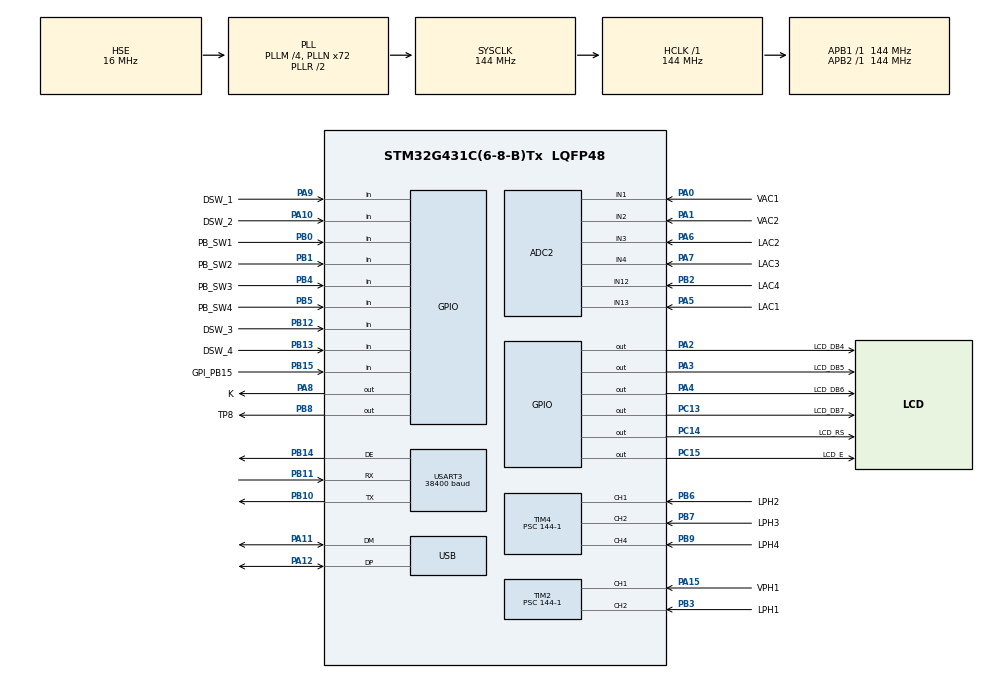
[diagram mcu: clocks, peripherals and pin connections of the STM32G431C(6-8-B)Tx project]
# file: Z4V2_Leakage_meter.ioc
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ADC1.Channel-0\#ChannelRegularConversion=ADC_CHANNEL_TEMPSENSOR_ADC1
ADC1.Channel-1\#ChannelRegularConversion=ADC_CHANNEL_VBAT
ADC1.Channel-2\#ChannelRegularConversion=ADC_CHANNEL_VREFINT
ADC1.DMAContinuousRequests=ENABLE
ADC1.ExternalTrigConv=ADC_EXTERNALTRIG_T7_TRGO
ADC1.NbrOfConversion=3
ADC1.NbrOfConversionFlag=1
ADC1.OffsetNumber-0\#ChannelRegularConversion=ADC_OFFSET_NONE
ADC1.OffsetNumber-1\#ChannelRegularConversion=ADC_OFFSET_NONE
ADC1.OffsetNumber-2\#ChannelRegularConversion=ADC_OFFSET_NONE
ADC1.Rank-0\#ChannelRegularConversion=1
ADC1.Rank-1\#ChannelRegularConversion=2
ADC1.Rank-2\#ChannelRegularConversion=3
ADC1.SamplingTime-0\#ChannelRegularConversion=ADC_SAMPLETIME_640CYCLES_5
ADC1.SamplingTime-1\#ChannelRegularConversion=ADC_SAMPLETIME_640CYCLES_5
ADC1.SamplingTime-2\#ChannelRegularConversion=ADC_SAMPLETIME_640CYCLES_5
ADC1.master=1
ADC2.Channel-0\#ChannelRegularConversion=ADC_CHANNEL_1
ADC2.Channel-1\#ChannelRegularConversion=ADC_CHANNEL_2
ADC2.Channel-2\#ChannelRegularConversion=ADC_CHANNEL_13
ADC2.Channel-3\#ChannelRegularConversion=ADC_CHANNEL_3
ADC2.Channel-4\#ChannelRegularConversion=ADC_CHANNEL_4
ADC2.Channel-5\#ChannelRegularConversion=ADC_CHANNEL_12
ADC2.DMAContinuousRequests=ENABLE
ADC2.ExternalTrigConv=ADC_EXTERNALTRIG_T8_TRGO
ADC2.NbrOfConversion=6
ADC2.NbrOfConversionFlag=1
ADC2.OffsetNumber-0\#ChannelRegularConversion=ADC_OFFSET_NONE
ADC2.OffsetNumber-1\#ChannelRegularConversion=ADC_OFFSET_NONE
ADC2.OffsetNumber-2\#ChannelRegularConversion=ADC_OFFSET_NONE
ADC2.OffsetNumber-3\#ChannelRegularConversion=ADC_OFFSET_NONE
ADC2.OffsetNumber-4\#ChannelRegularConversion=ADC_OFFSET_NONE
ADC2.OffsetNumber-5\#ChannelRegularConversion=ADC_OFFSET_NONE
ADC2.Rank-0\#ChannelRegularConversion=1
ADC2.Rank-1\#ChannelRegularConversion=2
ADC2.Rank-2\#ChannelRegularConversion=3
ADC2.Rank-3\#ChannelRegularConversion=4
ADC2.Rank-4\#ChannelRegularConversion=5
ADC2.Rank-5\#ChannelRegularConversion=6
ADC2.SamplingTime-0\#ChannelRegularConversion=ADC_SAMPLETIME_47CYCLES_5
ADC2.SamplingTime-1\#ChannelRegularConversion=ADC_SAMPLETIME_47CYCLES_5
ADC2.SamplingTime-2\#ChannelRegularConversion=ADC_SAMPLETIME_47CYCLES_5
ADC2.SamplingTime-3\#ChannelRegularConversion=ADC_SAMPLETIME_47CYCLES_5
ADC2.SamplingTime-4\#ChannelRegularConversion=ADC_SAMPLETIME_47CYCLES_5
ADC2.SamplingTime-5\#ChannelRegularConversion=ADC_SAMPLETIME_47CYCLES_5
Dma.ADC1.1.Direction=DMA_PERIPH_TO_MEMORY
Dma.ADC1.1.EventEnable=DISABLE
Dma.ADC1.1.Instance=DMA1_Channel2
Dma.ADC1.1.MemDataAlignment=DMA_MDATAALIGN_HALFWORD
Dma.ADC1.1.MemInc=DMA_MINC_ENABLE
Dma.ADC1.1.Mode=DMA_CIRCULAR
Dma.ADC1.1.PeriphDataAlignment=DMA_PDATAALIGN_HALFWORD
Dma.ADC1.1.PeriphInc=DMA_PINC_DISABLE
Dma.ADC1.1.Polarity=HAL_DMAMUX_REQ_GEN_RISING
Dma.ADC1.1.Priority=DMA_PRIORITY_LOW
Dma.ADC1.1.RequestNumber=1
Dma.ADC1.1.SignalID=NONE
Dma.ADC1.1.SyncEnable=DISABLE
Dma.ADC1.1.SyncPolarity=HAL_DMAMUX_SYNC_NO_EVENT
Dma.ADC1.1.SyncRequestNumber=1
Dma.ADC1.1.SyncSignalID=NONE
Dma.ADC2.0.Direction=DMA_PERIPH_TO_MEMORY
Dma.ADC2.0.EventEnable=DISABLE
Dma.ADC2.0.Instance=DMA1_Channel1
Dma.ADC2.0.MemDataAlignment=DMA_MDATAALIGN_HALFWORD
Dma.ADC2.0.MemInc=DMA_MINC_ENABLE
Dma.ADC2.0.Mode=DMA_CIRCULAR
Dma.ADC2.0.PeriphDataAlignment=DMA_PDATAALIGN_HALFWORD
Dma.ADC2.0.PeriphInc=DMA_PINC_DISABLE
Dma.ADC2.0.Polarity=HAL_DMAMUX_REQ_GEN_RISING
Dma.ADC2.0.Priority=DMA_PRIORITY_LOW
Dma.ADC2.0.RequestNumber=1
Dma.ADC2.0.SignalID=NONE
Dma.ADC2.0.SyncEnable=DISABLE
Dma.ADC2.0.SyncPolarity=HAL_DMAMUX_SYNC_NO_EVENT
Dma.ADC2.0.SyncRequestNumber=1
Dma.ADC2.0.SyncSignalID=NONE
Dma.Request0=ADC2
Dma.Request1=ADC1
FREERTOS.BinarySemaphores01=binSem_Flash,Static,binSem_ControlBlock,Available
FREERTOS.Queues01=queue_ADC,8,uint8_t,0,Static,queue_ADCBuffer,queue_ADCControlBlock;queue_USB,128,uint16_t,0,Static,queue_USBBuffer,queue_USBControlBlock
FREERTOS.Tasks01=tsk_USB,24,256,Start_tskUSB,Default,NULL,Static,tsk_USBBuffer,tsk_USBControlBlock;tsk_Calc,16,256,Start_tskCalc,Default,NULL,Static,tsk_CalcBuffer,tsk_CalcControlBlock;tsk_Ul,8,256,Start_taskUI,Default,NULL,Static,tsk_UlBuffer,tsk_UlControlBlock;tsk_MODBUS,40,128,Start_taskModbus,Default,NULL,Static,tsk_MODBUSBuffer,tsk_MODBUSControlBlock
FREERTOS.configENABLE_FPU=1
Mcu.Family=STM32G4
Mcu.Name=STM32G431C(6-8-B)Tx
Mcu.Package=LQFP48
NVIC.ADC1_2_IRQn=true\:5\:0\:false\:false\:true\:true\:true\:true\:true
NVIC.DMA1_Channel1_IRQn=true\:5\:0\:false\:false\:true\:true\:false\:true\:true
NVIC.DMA1_Channel2_IRQn=true\:5\:0\:false\:false\:true\:true\:false\:true\:true
NVIC.PriorityGroup=NVIC_PRIORITYGROUP_4
NVIC.TIM1_TRG_COM_TIM17_IRQn=true\:5\:0\:false\:false\:true\:false\:false\:true\:true
NVIC.TIM1_UP_TIM16_IRQn=true\:5\:0\:false\:false\:true\:true\:true\:true\:true
NVIC.TIM2_IRQn=true\:5\:0\:false\:false\:true\:true\:true\:true\:true
NVIC.TIM4_IRQn=true\:5\:0\:false\:false\:true\:true\:true\:true\:true
NVIC.TimeBase=TIM1_TRG_COM_TIM17_IRQn
NVIC.TimeBaseIP=TIM17
NVIC.USART3_IRQn=true\:5\:0\:false\:false\:true\:true\:true\:true\:true
NVIC.USB_LP_IRQn=true\:5\:0\:false\:false\:true\:true\:false\:true\:true
PA0.GPIO_Label=VAC1
PA0.Mode=IN1-Single-Ended
PA0.Signal=ADC2_IN1
PA1.GPIO_Label=VAC2
PA1.Mode=IN2-Single-Ended
PA1.Signal=ADC2_IN2
PA10.GPIO_Label=DSW_2
PA10.Signal=GPIO_Input
PA11.Mode=Device
PA11.Signal=USB_DM
PA12.Mode=Device
PA12.Signal=USB_DP
PA13.Mode=Serial_Wire
PA13.Signal=SYS_JTMS-SWDIO
PA14.Mode=Serial_Wire
PA14.Signal=SYS_JTCK-SWCLK
PA15.GPIO_Label=VPH1
PA15.Signal=S_TIM2_CH1
PA2.GPIO_Label=LCD_DB4
PA2.Signal=GPIO_Output
PA3.GPIO_Label=LCD_DB5
PA3.Signal=GPIO_Output
PA4.GPIO_Label=LCD_DB6
PA4.Signal=GPIO_Output
PA5.GPIO_Label=LAC1
PA5.Mode=IN13-Single-Ended
PA5.Signal=ADC2_IN13
PA6.GPIO_Label=LAC2
PA6.Mode=IN3-Single-Ended
PA6.Signal=ADC2_IN3
PA7.GPIO_Label=LAC3
PA7.Mode=IN4-Single-Ended
PA7.Signal=ADC2_IN4
PA8.GPIO_Label=K
PA8.Signal=GPIO_Output
PA9.GPIO_Label=DSW_1
PA9.Signal=GPIO_Input
PB0.GPIO_Label=PB_SW1
PB0.Signal=GPIO_Input
PB1.GPIO_Label=PB_SW2
PB1.Signal=GPIO_Input
PB10.Mode=Asynchronous
PB10.Signal=USART3_TX
PB11.Mode=Asynchronous
PB11.Signal=USART3_RX
PB12.GPIO_Label=DSW_3
PB12.Signal=GPIO_Input
PB13.GPIO_Label=DSW_4
PB13.Signal=GPIO_Input
PB14.Mode=Hardware Flow Control (RS485)
PB14.Signal=USART3_DE
PB15.GPIO_Label=GPI_PB15
PB15.Signal=GPIO_Input
PB2.GPIO_Label=LAC4
PB2.Mode=IN12-Single-Ended
PB2.Signal=ADC2_IN12
PB3.GPIO_Label=LPH1
PB3.Signal=S_TIM2_CH2
PB4.GPIO_Label=PB_SW3
PB4.Signal=GPIO_Input
PB5.GPIO_Label=PB_SW4
PB5.Signal=GPIO_Input
PB6.GPIO_Label=LPH2
PB6.Signal=S_TIM4_CH1
PB7.GPIO_Label=LPH3
PB7.Signal=S_TIM4_CH2
PB8-BOOT0.GPIO_Label=TP8
PB8-BOOT0.Signal=GPIO_Output
PB9.GPIO_Label=LPH4
PB9.Signal=S_TIM4_CH4
PC13.GPIO_Label=LCD_DB7
PC13.Signal=GPIO_Output
PC14-OSC32_IN.GPIO_Label=LCD_RS
PC14-OSC32_IN.Signal=GPIO_Output
PC15-OSC32_OUT.GPIO_Label=LCD_E
PC15-OSC32_OUT.Signal=GPIO_Output
PF0-OSC_IN.Mode=HSE-External-Oscillator
PF0-OSC_IN.Signal=RCC_OSC_IN
PF1-OSC_OUT.Mode=HSE-External-Oscillator
PF1-OSC_OUT.Signal=RCC_OSC_OUT
ProjectManager.HeapSize=0x200
ProjectManager.StackSize=0x400
ProjectManager.TargetToolchain=STM32CubeIDE
RCC.ADC12Freq_Value=144000000
RCC.AHBFreq_Value=144000000
RCC.APB1Freq_Value=144000000
RCC.APB1TimFreq_Value=144000000
RCC.APB2Freq_Value=144000000
RCC.APB2TimFreq_Value=144000000
RCC.CK48CLockSelection=RCC_USBCLKSOURCE_HSI48
RCC.CortexFreq_Value=144000000
RCC.EXTERNAL_CLOCK_VALUE=12288000
RCC.HCLKFreq_Value=144000000
RCC.HSE_VALUE=16000000
RCC.HSI48_VALUE=48000000
RCC.HSI_VALUE=16000000
RCC.LSE_VALUE=32768
RCC.PLLM=RCC_PLLM_DIV4
RCC.PLLN=72
RCC.PLLQ=RCC_PLLQ_DIV4
RCC.PLLSourceVirtual=RCC_PLLSOURCE_HSE
RCC.SYSCLKFreq_VALUE=144000000
RCC.SYSCLKSource=RCC_SYSCLKSOURCE_PLLCLK
RCC.USBFreq_Value=48000000
RCC.VCOOutputFreq_Value=288000000
SH.S_TIM2_CH1.0=TIM2_CH1,Input_Capture1_from_TI1
SH.S_TIM2_CH2.0=TIM2_CH2,Input_Capture2_from_TI2
SH.S_TIM4_CH1.0=TIM4_CH1,Input_Capture1_from_TI1
SH.S_TIM4_CH2.0=TIM4_CH2,Input_Capture2_from_TI2
SH.S_TIM4_CH4.0=TIM4_CH4,Input_Capture4_from_TI4
TIM1.PeriodNoDither=144-1
TIM1.Prescaler=1000-1
TIM15.Prescaler=1440-1
TIM2.Channel-Input_Capture1_from_TI1=TIM_CHANNEL_1
TIM2.Channel-Input_Capture2_from_TI2=TIM_CHANNEL_2
TIM2.ICPolarity_CH1=TIM_INPUTCHANNELPOLARITY_RISING
TIM2.ICPolarity_CH2=TIM_INPUTCHANNELPOLARITY_RISING
TIM2.PeriodNoDither=65535
TIM2.Prescaler=144-1
TIM2.TIM_MasterOutputTrigger=TIM_TRGO_RESET
TIM2.TIM_MasterSlaveMode=TIM_MASTERSLAVEMODE_DISABLE
TIM3.PeriodNoDither=65535
TIM3.Prescaler=144-1
TIM3.TIM_MasterOutputTrigger=TIM_TRGO_UPDATE
TIM3.TIM_MasterSlaveMode=TIM_MASTERSLAVEMODE_ENABLE
TIM4.Channel-Input_Capture1_from_TI1=TIM_CHANNEL_1
TIM4.Channel-Input_Capture2_from_TI2=TIM_CHANNEL_2
TIM4.Channel-Input_Capture4_from_TI4=TIM_CHANNEL_4
TIM4.ICPolarity_CH1=TIM_INPUTCHANNELPOLARITY_RISING
TIM4.ICPolarity_CH2=TIM_INPUTCHANNELPOLARITY_RISING
TIM4.ICPolarity_CH4=TIM_INPUTCHANNELPOLARITY_RISING
TIM4.Prescaler=144-1
TIM4.TIM_MasterOutputTrigger=TIM_TRGO_RESET
TIM4.TIM_MasterSlaveMode=TIM_MASTERSLAVEMODE_DISABLE
TIM7.PeriodNoDither=10000-1
TIM7.Prescaler=14400-1
TIM7.TIM_MasterOutputTrigger=TIM_TRGO_UPDATE
TIM8.PeriodNoDither=40000-1
TIM8.TIM_MasterOutputTrigger=TIM_TRGO_UPDATE
USART3.BaudRate=38400
USART3.FIFOMode=FIFOMODE_ENABLE
USART3.StopBits=STOPBITS_2
USART3.VirtualMode-Asynchronous=VM_ASYNC
USART3.VirtualMode-Hardware\ Flow\ Control\ (RS485)=VM_ASYNC
USB_DEVICE.CLASS_NAME_FS=CDC
USB_DEVICE.VirtualMode=Cdc
USB_DEVICE.VirtualModeFS=Cdc_FS
VP_ADC1_TempSens_Input.Mode=IN-TempSens
VP_ADC1_Vbat_Input.Mode=IN-Vbat
VP_ADC1_Vref_Input.Mode=IN-Vrefint
VP_CRC_VS_CRC.Mode=CRC_Activate
VP_FREERTOS_VS_CMSIS_V2.Mode=CMSIS_V2
VP_SYS_VS_DBSignals.Mode=DisableDeadBatterySignals
VP_SYS_VS_tim17.Mode=TIM17
VP_TIM15_VS_ClockSourceINT.Mode=Internal
VP_TIM1_VS_ClockSourceINT.Mode=Internal
VP_TIM2_VS_ClockSourceINT.Mode=Internal
VP_TIM2_VS_ClockSourceITR.Mode=TriggerSource_ITR2
VP_TIM2_VS_ControllerModeTrigger.Mode=Trigger Mode
VP_TIM3_VS_ClockSourceINT.Mode=Internal
VP_TIM4_VS_ClockSourceINT.Mode=Internal
VP_TIM4_VS_ClockSourceITR.Mode=TriggerSource_ITR2
VP_TIM4_VS_ControllerModeTrigger.Mode=Trigger Mode
VP_TIM7_VS_ClockSourceINT.Mode=Enable_Timer
VP_TIM8_VS_ClockSourceINT.Mode=Internal
VP_USB_DEVICE_VS_USB_DEVICE_CDC_FS.Mode=CDC_FS
board=custom

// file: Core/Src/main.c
/* USER CODE BEGIN Header */
/**
  ******************************************************************************
  * @file           : main.c
  * @brief          : Main program body
  ******************************************************************************
  * @attention
  *
  * Copyright (c) 2026 STMicroelectronics.
  * All rights reserved.
  *
  * This software is licensed under terms that can be found in the LICENSE file
  * in the root directory of this software component.
  * If no LICENSE file comes with this software, it is provided AS-IS.
  *
  ******************************************************************************
  */
/* USER CODE END Header */
#include "main.h"
#include "cmsis_os.h"
#include "usb_device.h"

/* USER CODE BEGIN Includes */
#include "prj.h"
/* USER CODE END Includes */

typedef StaticTask_t osStaticThreadDef_t;
typedef StaticQueue_t osStaticMessageQDef_t;
typedef StaticSemaphore_t osStaticSemaphoreDef_t;

ADC_HandleTypeDef hadc1;
ADC_HandleTypeDef hadc2;
DMA_HandleTypeDef hdma_adc1;
DMA_HandleTypeDef hdma_adc2;

CRC_HandleTypeDef hcrc;

TIM_HandleTypeDef htim1;
TIM_HandleTypeDef htim2;
TIM_HandleTypeDef htim3;
TIM_HandleTypeDef htim4;
TIM_HandleTypeDef htim7;
TIM_HandleTypeDef htim8;
TIM_HandleTypeDef htim15;

UART_HandleTypeDef huart3;

/* Definitions for tsk_USB */
osThreadId_t tsk_USBHandle;
uint32_t tsk_USBBuffer[ 256 ];
osStaticThreadDef_t tsk_USBControlBlock;
const osThreadAttr_t tsk_USB_attributes = {
  .name = "tsk_USB",
  .stack_mem = &tsk_USBBuffer[0],
  .stack_size = sizeof(tsk_USBBuffer),
  .cb_mem = &tsk_USBControlBlock,
  .cb_size = sizeof(tsk_USBControlBlock),
  .priority = (osPriority_t) osPriorityNormal,
};
/* Definitions for tsk_Calc */
osThreadId_t tsk_CalcHandle;
uint32_t tsk_CalcBuffer[ 256 ];
osStaticThreadDef_t tsk_CalcControlBlock;
const osThreadAttr_t tsk_Calc_attributes = {
  .name = "tsk_Calc",
  .stack_mem = &tsk_CalcBuffer[0],
  .stack_size = sizeof(tsk_CalcBuffer),
  .cb_mem = &tsk_CalcControlBlock,
  .cb_size = sizeof(tsk_CalcControlBlock),
  .priority = (osPriority_t) osPriorityBelowNormal,
};
/* Definitions for tsk_Ul */
osThreadId_t tsk_UlHandle;
uint32_t tsk_UlBuffer[ 256 ];
osStaticThreadDef_t tsk_UlControlBlock;
const osThreadAttr_t tsk_Ul_attributes = {
  .name = "tsk_Ul",
  .stack_mem = &tsk_UlBuffer[0],
  .stack_size = sizeof(tsk_UlBuffer),
  .cb_mem = &tsk_UlControlBlock,
  .cb_size = sizeof(tsk_UlControlBlock),
  .priority = (osPriority_t) osPriorityLow,
};
/* Definitions for tsk_MODBUS */
osThreadId_t tsk_MODBUSHandle;
uint32_t tsk_MODBUSBuffer[ 128 ];
osStaticThreadDef_t tsk_MODBUSControlBlock;
const osThreadAttr_t tsk_MODBUS_attributes = {
  .name = "tsk_MODBUS",
  .stack_mem = &tsk_MODBUSBuffer[0],
  .stack_size = sizeof(tsk_MODBUSBuffer),
  .cb_mem = &tsk_MODBUSControlBlock,
  .cb_size = sizeof(tsk_MODBUSControlBlock),
  .priority = (osPriority_t) osPriorityHigh,
};
/* Definitions for queue_ADC */
osMessageQueueId_t queue_ADCHandle;
uint8_t queue_ADCBuffer[ 8 * sizeof( uint8_t ) ];
osStaticMessageQDef_t queue_ADCControlBlock;
const osMessageQueueAttr_t queue_ADC_attributes = {
  .name = "queue_ADC",
  .cb_mem = &queue_ADCControlBlock,
  .cb_size = sizeof(queue_ADCControlBlock),
  .mq_mem = &queue_ADCBuffer,
  .mq_size = sizeof(queue_ADCBuffer)
};
/* Definitions for queue_USB */
osMessageQueueId_t queue_USBHandle;
uint8_t queue_USBBuffer[ 128 * sizeof( uint16_t ) ];
osStaticMessageQDef_t queue_USBControlBlock;
const osMessageQueueAttr_t queue_USB_attributes = {
  .name = "queue_USB",
  .cb_mem = &queue_USBControlBlock,
  .cb_size = sizeof(queue_USBControlBlock),
  .mq_mem = &queue_USBBuffer,
  .mq_size = sizeof(queue_USBBuffer)
};
/* Definitions for binSem_Flash */
osSemaphoreId_t binSem_FlashHandle;
osStaticSemaphoreDef_t binSem_ControlBlock;
const osSemaphoreAttr_t binSem_Flash_attributes = {
  .name = "binSem_Flash",
  .cb_mem = &binSem_ControlBlock,
  .cb_size = sizeof(binSem_ControlBlock),
};

void SystemClock_Config(void);
static void MX_GPIO_Init(void);
static void MX_DMA_Init(void);
static void MX_ADC2_Init(void);
static void MX_TIM3_Init(void);
static void MX_TIM4_Init(void);
static void MX_USART3_UART_Init(void);
static void MX_TIM2_Init(void);
static void MX_ADC1_Init(void);
static void MX_TIM7_Init(void);
static void MX_TIM8_Init(void);
static void MX_CRC_Init(void);
static void MX_TIM15_Init(void);
static void MX_TIM1_Init(void);
void Start_tskUSB(void *argument);
void Start_tskCalc(void *argument);
void Start_taskUI(void *argument);
void Start_taskModbus(void *argument);

int main(void)
{

  /* MCU Configuration--------------------------------------------------------*/

  /* Reset of all peripherals, Initializes the Flash interface and the Systick. */
  HAL_Init();

  /* Configure the system clock */
  SystemClock_Config();

  /* Initialize all configured peripherals */
  MX_GPIO_Init();
  MX_DMA_Init();
  MX_ADC2_Init();
  MX_TIM3_Init();
  MX_TIM4_Init();
  MX_USART3_UART_Init();
  MX_TIM2_Init();
  MX_ADC1_Init();
  MX_TIM7_Init();
  MX_TIM8_Init();
  MX_CRC_Init();
  MX_TIM15_Init();
  MX_TIM1_Init();

  /* Init scheduler */
  osKernelInitialize();

  /* Create the semaphores(s) */
  /* creation of binSem_Flash */
  binSem_FlashHandle = osSemaphoreNew(1, 1, &binSem_Flash_attributes);

  /* Create the queue(s) */
  /* creation of queue_ADC */
  queue_ADCHandle = osMessageQueueNew (8, sizeof(uint8_t), &queue_ADC_attributes);

  /* creation of queue_USB */
  queue_USBHandle = osMessageQueueNew (128, sizeof(uint16_t), &queue_USB_attributes);

  /* Create the thread(s) */
  /* creation of tsk_USB */
  tsk_USBHandle = osThreadNew(Start_tskUSB, NULL, &tsk_USB_attributes);

  /* creation of tsk_Calc */
  tsk_CalcHandle = osThreadNew(Start_tskCalc, NULL, &tsk_Calc_attributes);

  /* creation of tsk_Ul */
  tsk_UlHandle = osThreadNew(Start_taskUI, NULL, &tsk_Ul_attributes);

  /* creation of tsk_MODBUS */
  tsk_MODBUSHandle = osThreadNew(Start_taskModbus, NULL, &tsk_MODBUS_attributes);

  /* Start scheduler */
  osKernelStart();

  /* We should never get here as control is now taken by the scheduler */

  /* Infinite loop */
  while (1)
  {

  }
}

void SystemClock_Config(void)
{
  RCC_OscInitTypeDef RCC_OscInitStruct = {0};
  RCC_ClkInitTypeDef RCC_ClkInitStruct = {0};

  /** Configure the main internal regulator output voltage
  */
  HAL_PWREx_ControlVoltageScaling(PWR_REGULATOR_VOLTAGE_SCALE1);

  /** Initializes the RCC Oscillators according to the specified parameters
  * in the RCC_OscInitTypeDef structure.
  */
  RCC_OscInitStruct.OscillatorType = RCC_OSCILLATORTYPE_HSI48|RCC_OSCILLATORTYPE_HSE;
  RCC_OscInitStruct.HSEState = RCC_HSE_ON;
  RCC_OscInitStruct.HSI48State = RCC_HSI48_ON;
  RCC_OscInitStruct.PLL.PLLState = RCC_PLL_ON;
  RCC_OscInitStruct.PLL.PLLSource = RCC_PLLSOURCE_HSE;
  RCC_OscInitStruct.PLL.PLLM = RCC_PLLM_DIV4;
  RCC_OscInitStruct.PLL.PLLN = 72;
  RCC_OscInitStruct.PLL.PLLP = RCC_PLLP_DIV2;
  RCC_OscInitStruct.PLL.PLLQ = RCC_PLLQ_DIV4;
  RCC_OscInitStruct.PLL.PLLR = RCC_PLLR_DIV2;
  if (HAL_RCC_OscConfig(&RCC_OscInitStruct) != HAL_OK)
  {
    Error_Handler();
  }

  /** Initializes the CPU, AHB and APB buses clocks
  */
  RCC_ClkInitStruct.ClockType = RCC_CLOCKTYPE_HCLK|RCC_CLOCKTYPE_SYSCLK
                              |RCC_CLOCKTYPE_PCLK1|RCC_CLOCKTYPE_PCLK2;
  RCC_ClkInitStruct.SYSCLKSource = RCC_SYSCLKSOURCE_PLLCLK;
  RCC_ClkInitStruct.AHBCLKDivider = RCC_SYSCLK_DIV1;
  RCC_ClkInitStruct.APB1CLKDivider = RCC_HCLK_DIV1;
  RCC_ClkInitStruct.APB2CLKDivider = RCC_HCLK_DIV1;

  if (HAL_RCC_ClockConfig(&RCC_ClkInitStruct, FLASH_LATENCY_4) != HAL_OK)
  {
    Error_Handler();
  }
}

static void MX_ADC1_Init(void)
{

  ADC_MultiModeTypeDef multimode = {0};
  ADC_ChannelConfTypeDef sConfig = {0};

  /** Common config
  */
  hadc1.Instance = ADC1;
  hadc1.Init.ClockPrescaler = ADC_CLOCK_SYNC_PCLK_DIV4;
  hadc1.Init.Resolution = ADC_RESOLUTION_12B;
  hadc1.Init.DataAlign = ADC_DATAALIGN_RIGHT;
  hadc1.Init.GainCompensation = 0;
  hadc1.Init.ScanConvMode = ADC_SCAN_ENABLE;
  hadc1.Init.EOCSelection = ADC_EOC_SINGLE_CONV;
  hadc1.Init.LowPowerAutoWait = DISABLE;
  hadc1.Init.ContinuousConvMode = DISABLE;
  hadc1.Init.NbrOfConversion = 3;
  hadc1.Init.DiscontinuousConvMode = DISABLE;
  hadc1.Init.ExternalTrigConv = ADC_EXTERNALTRIG_T7_TRGO;
  hadc1.Init.ExternalTrigConvEdge = ADC_EXTERNALTRIGCONVEDGE_RISING;
  hadc1.Init.DMAContinuousRequests = ENABLE;
  hadc1.Init.Overrun = ADC_OVR_DATA_PRESERVED;
  hadc1.Init.OversamplingMode = DISABLE;
  if (HAL_ADC_Init(&hadc1) != HAL_OK)
  {
    Error_Handler();
  }

  /** Configure the ADC multi-mode
  */
  multimode.Mode = ADC_MODE_INDEPENDENT;
  if (HAL_ADCEx_MultiModeConfigChannel(&hadc1, &multimode) != HAL_OK)
  {
    Error_Handler();
  }

  /** Configure Regular Channel
  */
  sConfig.Channel = ADC_CHANNEL_TEMPSENSOR_ADC1;
  sConfig.Rank = ADC_REGULAR_RANK_1;
  sConfig.SamplingTime = ADC_SAMPLETIME_640CYCLES_5;
  sConfig.SingleDiff = ADC_SINGLE_ENDED;
  sConfig.OffsetNumber = ADC_OFFSET_NONE;
  sConfig.Offset = 0;
  if (HAL_ADC_ConfigChannel(&hadc1, &sConfig) != HAL_OK)
  {
    Error_Handler();
  }

  /** Configure Regular Channel
  */
  sConfig.Channel = ADC_CHANNEL_VBAT;
  sConfig.Rank = ADC_REGULAR_RANK_2;
  if (HAL_ADC_ConfigChannel(&hadc1, &sConfig) != HAL_OK)
  {
    Error_Handler();
  }

  /** Configure Regular Channel
  */
  sConfig.Channel = ADC_CHANNEL_VREFINT;
  sConfig.Rank = ADC_REGULAR_RANK_3;
  if (HAL_ADC_ConfigChannel(&hadc1, &sConfig) != HAL_OK)
  {
    Error_Handler();
  }

}

static void MX_ADC2_Init(void)
{

  ADC_ChannelConfTypeDef sConfig = {0};

  /** Common config
  */
  hadc2.Instance = ADC2;
  hadc2.Init.ClockPrescaler = ADC_CLOCK_SYNC_PCLK_DIV4;
  hadc2.Init.Resolution = ADC_RESOLUTION_12B;
  hadc2.Init.DataAlign = ADC_DATAALIGN_RIGHT;
  hadc2.Init.GainCompensation = 0;
  hadc2.Init.ScanConvMode = ADC_SCAN_ENABLE;
  hadc2.Init.EOCSelection = ADC_EOC_SINGLE_CONV;
  hadc2.Init.LowPowerAutoWait = DISABLE;
  hadc2.Init.ContinuousConvMode = DISABLE;
  hadc2.Init.NbrOfConversion = 6;
  hadc2.Init.DiscontinuousConvMode = DISABLE;
  hadc2.Init.ExternalTrigConv = ADC_EXTERNALTRIG_T8_TRGO;
  hadc2.Init.ExternalTrigConvEdge = ADC_EXTERNALTRIGCONVEDGE_RISING;
  hadc2.Init.DMAContinuousRequests = ENABLE;
  hadc2.Init.Overrun = ADC_OVR_DATA_PRESERVED;
  hadc2.Init.OversamplingMode = DISABLE;
  if (HAL_ADC_Init(&hadc2) != HAL_OK)
  {
    Error_Handler();
  }

  /** Configure Regular Channel
  */
  sConfig.Channel = ADC_CHANNEL_1;
  sConfig.Rank = ADC_REGULAR_RANK_1;
  sConfig.SamplingTime = ADC_SAMPLETIME_47CYCLES_5;
  sConfig.SingleDiff = ADC_SINGLE_ENDED;
  sConfig.OffsetNumber = ADC_OFFSET_NONE;
  sConfig.Offset = 0;
  if (HAL_ADC_ConfigChannel(&hadc2, &sConfig) != HAL_OK)
  {
    Error_Handler();
  }

  /** Configure Regular Channel
  */
  sConfig.Channel = ADC_CHANNEL_2;
  sConfig.Rank = ADC_REGULAR_RANK_2;
  if (HAL_ADC_ConfigChannel(&hadc2, &sConfig) != HAL_OK)
  {
    Error_Handler();
  }

  /** Configure Regular Channel
  */
  sConfig.Channel = ADC_CHANNEL_13;
  sConfig.Rank = ADC_REGULAR_RANK_3;
  if (HAL_ADC_ConfigChannel(&hadc2, &sConfig) != HAL_OK)
  {
    Error_Handler();
  }

  /** Configure Regular Channel
  */
  sConfig.Channel = ADC_CHANNEL_3;
  sConfig.Rank = ADC_REGULAR_RANK_4;
  if (HAL_ADC_ConfigChannel(&hadc2, &sConfig) != HAL_OK)
  {
    Error_Handler();
  }

  /** Configure Regular Channel
  */
  sConfig.Channel = ADC_CHANNEL_4;
  sConfig.Rank = ADC_REGULAR_RANK_5;
  if (HAL_ADC_ConfigChannel(&hadc2, &sConfig) != HAL_OK)
  {
    Error_Handler();
  }

  /** Configure Regular Channel
  */
  sConfig.Channel = ADC_CHANNEL_12;
  sConfig.Rank = ADC_REGULAR_RANK_6;
  if (HAL_ADC_ConfigChannel(&hadc2, &sConfig) != HAL_OK)
  {
    Error_Handler();
  }

}

static void MX_CRC_Init(void)
{

  hcrc.Instance = CRC;
  hcrc.Init.DefaultPolynomialUse = DEFAULT_POLYNOMIAL_ENABLE;
  hcrc.Init.DefaultInitValueUse = DEFAULT_INIT_VALUE_ENABLE;
  hcrc.Init.InputDataInversionMode = CRC_INPUTDATA_INVERSION_NONE;
  hcrc.Init.OutputDataInversionMode = CRC_OUTPUTDATA_INVERSION_DISABLE;
  hcrc.InputDataFormat = CRC_INPUTDATA_FORMAT_BYTES;
  if (HAL_CRC_Init(&hcrc) != HAL_OK)
  {
    Error_Handler();
  }

}

static void MX_TIM1_Init(void)
{

  TIM_ClockConfigTypeDef sClockSourceConfig = {0};
  TIM_MasterConfigTypeDef sMasterConfig = {0};

  htim1.Instance = TIM1;
  htim1.Init.Prescaler = 1000-1;
  htim1.Init.CounterMode = TIM_COUNTERMODE_UP;
  htim1.Init.Period = 143;
  htim1.Init.ClockDivision = TIM_CLOCKDIVISION_DIV1;
  htim1.Init.RepetitionCounter = 0;
  htim1.Init.AutoReloadPreload = TIM_AUTORELOAD_PRELOAD_DISABLE;
  if (HAL_TIM_Base_Init(&htim1) != HAL_OK)
  {
    Error_Handler();
  }
  sClockSourceConfig.ClockSource = TIM_CLOCKSOURCE_INTERNAL;
  if (HAL_TIM_ConfigClockSource(&htim1, &sClockSourceConfig) != HAL_OK)
  {
    Error_Handler();
  }
  sMasterConfig.MasterOutputTrigger = TIM_TRGO_RESET;
  sMasterConfig.MasterOutputTrigger2 = TIM_TRGO2_RESET;
  sMasterConfig.MasterSlaveMode = TIM_MASTERSLAVEMODE_DISABLE;
  if (HAL_TIMEx_MasterConfigSynchronization(&htim1, &sMasterConfig) != HAL_OK)
  {
    Error_Handler();
  }

}

static void MX_TIM2_Init(void)
{

  TIM_ClockConfigTypeDef sClockSourceConfig = {0};
  TIM_SlaveConfigTypeDef sSlaveConfig = {0};
  TIM_MasterConfigTypeDef sMasterConfig = {0};
  TIM_IC_InitTypeDef sConfigIC = {0};

  htim2.Instance = TIM2;
  htim2.Init.Prescaler = 144-1;
  htim2.Init.CounterMode = TIM_COUNTERMODE_UP;
  htim2.Init.Period = 65535;
  htim2.Init.ClockDivision = TIM_CLOCKDIVISION_DIV1;
  htim2.Init.AutoReloadPreload = TIM_AUTORELOAD_PRELOAD_DISABLE;
  if (HAL_TIM_Base_Init(&htim2) != HAL_OK)
  {
    Error_Handler();
  }
  sClockSourceConfig.ClockSource = TIM_CLOCKSOURCE_INTERNAL;
  if (HAL_TIM_ConfigClockSource(&htim2, &sClockSourceConfig) != HAL_OK)
  {
    Error_Handler();
  }
  if (HAL_TIM_IC_Init(&htim2) != HAL_OK)
  {
    Error_Handler();
  }
  sSlaveConfig.SlaveMode = TIM_SLAVEMODE_TRIGGER;
  sSlaveConfig.InputTrigger = TIM_TS_ITR2;
  if (HAL_TIM_SlaveConfigSynchro(&htim2, &sSlaveConfig) != HAL_OK)
  {
    Error_Handler();
  }
  sMasterConfig.MasterOutputTrigger = TIM_TRGO_RESET;
  sMasterConfig.MasterSlaveMode = TIM_MASTERSLAVEMODE_DISABLE;
  if (HAL_TIMEx_MasterConfigSynchronization(&htim2, &sMasterConfig) != HAL_OK)
  {
    Error_Handler();
  }
  sConfigIC.ICPolarity = TIM_INPUTCHANNELPOLARITY_RISING;
  sConfigIC.ICSelection = TIM_ICSELECTION_DIRECTTI;
  sConfigIC.ICPrescaler = TIM_ICPSC_DIV1;
  sConfigIC.ICFilter = 0;
  if (HAL_TIM_IC_ConfigChannel(&htim2, &sConfigIC, TIM_CHANNEL_1) != HAL_OK)
  {
    Error_Handler();
  }
  if (HAL_TIM_IC_ConfigChannel(&htim2, &sConfigIC, TIM_CHANNEL_2) != HAL_OK)
  {
    Error_Handler();
  }

}

static void MX_TIM3_Init(void)
{

  TIM_ClockConfigTypeDef sClockSourceConfig = {0};
  TIM_MasterConfigTypeDef sMasterConfig = {0};

  htim3.Instance = TIM3;
  htim3.Init.Prescaler = 144-1;
  htim3.Init.CounterMode = TIM_COUNTERMODE_UP;
  htim3.Init.Period = 65535;
  htim3.Init.ClockDivision = TIM_CLOCKDIVISION_DIV1;
  htim3.Init.AutoReloadPreload = TIM_AUTORELOAD_PRELOAD_DISABLE;
  if (HAL_TIM_Base_Init(&htim3) != HAL_OK)
  {
    Error_Handler();
  }
  sClockSourceConfig.ClockSource = TIM_CLOCKSOURCE_INTERNAL;
  if (HAL_TIM_ConfigClockSource(&htim3, &sClockSourceConfig) != HAL_OK)
  {
    Error_Handler();
  }
  sMasterConfig.MasterOutputTrigger = TIM_TRGO_UPDATE;
  sMasterConfig.MasterSlaveMode = TIM_MASTERSLAVEMODE_ENABLE;
  if (HAL_TIMEx_MasterConfigSynchronization(&htim3, &sMasterConfig) != HAL_OK)
  {
    Error_Handler();
  }

}

static void MX_TIM4_Init(void)
{

  TIM_ClockConfigTypeDef sClockSourceConfig = {0};
  TIM_SlaveConfigTypeDef sSlaveConfig = {0};
  TIM_MasterConfigTypeDef sMasterConfig = {0};
  TIM_IC_InitTypeDef sConfigIC = {0};

  htim4.Instance = TIM4;
  htim4.Init.Prescaler = 144-1;
  htim4.Init.CounterMode = TIM_COUNTERMODE_UP;
  htim4.Init.Period = 65535;
  htim4.Init.ClockDivision = TIM_CLOCKDIVISION_DIV1;
  htim4.Init.AutoReloadPreload = TIM_AUTORELOAD_PRELOAD_DISABLE;
  if (HAL_TIM_Base_Init(&htim4) != HAL_OK)
  {
    Error_Handler();
  }
  sClockSourceConfig.ClockSource = TIM_CLOCKSOURCE_INTERNAL;
  if (HAL_TIM_ConfigClockSource(&htim4, &sClockSourceConfig) != HAL_OK)
  {
    Error_Handler();
  }
  if (HAL_TIM_IC_Init(&htim4) != HAL_OK)
  {
    Error_Handler();
  }
  sSlaveConfig.SlaveMode = TIM_SLAVEMODE_TRIGGER;
  sSlaveConfig.InputTrigger = TIM_TS_ITR2;
  if (HAL_TIM_SlaveConfigSynchro(&htim4, &sSlaveConfig) != HAL_OK)
  {
    Error_Handler();
  }
  sMasterConfig.MasterOutputTrigger = TIM_TRGO_RESET;
  sMasterConfig.MasterSlaveMode = TIM_MASTERSLAVEMODE_DISABLE;
  if (HAL_TIMEx_MasterConfigSynchronization(&htim4, &sMasterConfig) != HAL_OK)
  {
    Error_Handler();
  }
  sConfigIC.ICPolarity = TIM_INPUTCHANNELPOLARITY_RISING;
  sConfigIC.ICSelection = TIM_ICSELECTION_DIRECTTI;
  sConfigIC.ICPrescaler = TIM_ICPSC_DIV1;
  sConfigIC.ICFilter = 0;
  if (HAL_TIM_IC_ConfigChannel(&htim4, &sConfigIC, TIM_CHANNEL_1) != HAL_OK)
  {
    Error_Handler();
  }
  if (HAL_TIM_IC_ConfigChannel(&htim4, &sConfigIC, TIM_CHANNEL_2) != HAL_OK)
  {
    Error_Handler();
  }
  if (HAL_TIM_IC_ConfigChannel(&htim4, &sConfigIC, TIM_CHANNEL_4) != HAL_OK)
  {
    Error_Handler();
  }

}

static void MX_TIM7_Init(void)
{

  TIM_MasterConfigTypeDef sMasterConfig = {0};

  htim7.Instance = TIM7;
  htim7.Init.Prescaler = 14400-1;
  htim7.Init.CounterMode = TIM_COUNTERMODE_UP;
  htim7.Init.Period = 9999;
  htim7.Init.AutoReloadPreload = TIM_AUTORELOAD_PRELOAD_DISABLE;
  if (HAL_TIM_Base_Init(&htim7) != HAL_OK)
  {
    Error_Handler();
  }
  sMasterConfig.MasterOutputTrigger = TIM_TRGO_UPDATE;
  sMasterConfig.MasterSlaveMode = TIM_MASTERSLAVEMODE_DISABLE;
  if (HAL_TIMEx_MasterConfigSynchronization(&htim7, &sMasterConfig) != HAL_OK)
  {
    Error_Handler();
  }

}

static void MX_TIM8_Init(void)
{

  TIM_ClockConfigTypeDef sClockSourceConfig = {0};
  TIM_MasterConfigTypeDef sMasterConfig = {0};

  htim8.Instance = TIM8;
  htim8.Init.Prescaler = 0;
  htim8.Init.CounterMode = TIM_COUNTERMODE_UP;
  htim8.Init.Period = 39999;
  htim8.Init.ClockDivision = TIM_CLOCKDIVISION_DIV1;
  htim8.Init.RepetitionCounter = 0;
  htim8.Init.AutoReloadPreload = TIM_AUTORELOAD_PRELOAD_DISABLE;
  if (HAL_TIM_Base_Init(&htim8) != HAL_OK)
  {
    Error_Handler();
  }
  sClockSourceConfig.ClockSource = TIM_CLOCKSOURCE_INTERNAL;
  if (HAL_TIM_ConfigClockSource(&htim8, &sClockSourceConfig) != HAL_OK)
  {
    Error_Handler();
  }
  sMasterConfig.MasterOutputTrigger = TIM_TRGO_UPDATE;
  sMasterConfig.MasterOutputTrigger2 = TIM_TRGO2_RESET;
  sMasterConfig.MasterSlaveMode = TIM_MASTERSLAVEMODE_DISABLE;
  if (HAL_TIMEx_MasterConfigSynchronization(&htim8, &sMasterConfig) != HAL_OK)
  {
    Error_Handler();
  }

}

static void MX_TIM15_Init(void)
{

  TIM_ClockConfigTypeDef sClockSourceConfig = {0};
  TIM_MasterConfigTypeDef sMasterConfig = {0};

  htim15.Instance = TIM15;
  htim15.Init.Prescaler = 1440-1;
  htim15.Init.CounterMode = TIM_COUNTERMODE_UP;
  htim15.Init.Period = 65535;
  htim15.Init.ClockDivision = TIM_CLOCKDIVISION_DIV1;
  htim15.Init.RepetitionCounter = 0;
  htim15.Init.AutoReloadPreload = TIM_AUTORELOAD_PRELOAD_DISABLE;
  if (HAL_TIM_Base_Init(&htim15) != HAL_OK)
  {
    Error_Handler();
  }
  sClockSourceConfig.ClockSource = TIM_CLOCKSOURCE_INTERNAL;
  if (HAL_TIM_ConfigClockSource(&htim15, &sClockSourceConfig) != HAL_OK)
  {
    Error_Handler();
  }
  sMasterConfig.MasterOutputTrigger = TIM_TRGO_RESET;
  sMasterConfig.MasterSlaveMode = TIM_MASTERSLAVEMODE_DISABLE;
  if (HAL_TIMEx_MasterConfigSynchronization(&htim15, &sMasterConfig) != HAL_OK)
  {
    Error_Handler();
  }

}

static void MX_USART3_UART_Init(void)
{

  huart3.Instance = USART3;
  huart3.Init.BaudRate = 38400;
  huart3.Init.WordLength = UART_WORDLENGTH_8B;
  huart3.Init.StopBits = UART_STOPBITS_2;
  huart3.Init.Parity = UART_PARITY_NONE;
  huart3.Init.Mode = UART_MODE_TX_RX;
  huart3.Init.HwFlowCtl = UART_HWCONTROL_NONE;
  huart3.Init.OverSampling = UART_OVERSAMPLING_16;
  huart3.Init.OneBitSampling = UART_ONE_BIT_SAMPLE_DISABLE;
  huart3.Init.ClockPrescaler = UART_PRESCALER_DIV1;
  huart3.AdvancedInit.AdvFeatureInit = UART_ADVFEATURE_NO_INIT;
  if (HAL_RS485Ex_Init(&huart3, UART_DE_POLARITY_HIGH, 0, 0) != HAL_OK)
  {
    Error_Handler();
  }
  if (HAL_UARTEx_SetTxFifoThreshold(&huart3, UART_TXFIFO_THRESHOLD_1_8) != HAL_OK)
  {
    Error_Handler();
  }
  if (HAL_UARTEx_SetRxFifoThreshold(&huart3, UART_RXFIFO_THRESHOLD_1_8) != HAL_OK)
  {
    Error_Handler();
  }
  if (HAL_UARTEx_EnableFifoMode(&huart3) != HAL_OK)
  {
    Error_Handler();
  }

}

static void MX_DMA_Init(void)
{

  /* DMA controller clock enable */
  __HAL_RCC_DMAMUX1_CLK_ENABLE();
  __HAL_RCC_DMA1_CLK_ENABLE();

  /* DMA interrupt init */
  /* DMA1_Channel1_IRQn interrupt configuration */
  HAL_NVIC_SetPriority(DMA1_Channel1_IRQn, 5, 0);
  HAL_NVIC_EnableIRQ(DMA1_Channel1_IRQn);
  /* DMA1_Channel2_IRQn interrupt configuration */
  HAL_NVIC_SetPriority(DMA1_Channel2_IRQn, 5, 0);
  HAL_NVIC_EnableIRQ(DMA1_Channel2_IRQn);

}

static void MX_GPIO_Init(void)
{
  GPIO_InitTypeDef GPIO_InitStruct = {0};

  /* GPIO Ports Clock Enable */
  __HAL_RCC_GPIOC_CLK_ENABLE();
  __HAL_RCC_GPIOF_CLK_ENABLE();
  __HAL_RCC_GPIOA_CLK_ENABLE();
  __HAL_RCC_GPIOB_CLK_ENABLE();

  /*Configure GPIO pin Output Level */
  HAL_GPIO_WritePin(GPIOC, LCD_DB7_Pin|LCD_RS_Pin|LCD_E_Pin, GPIO_PIN_RESET);

  /*Configure GPIO pin Output Level */
  HAL_GPIO_WritePin(GPIOA, LCD_DB4_Pin|LCD_DB5_Pin|LCD_DB6_Pin|K_Pin, GPIO_PIN_RESET);

  /*Configure GPIO pin Output Level */
  HAL_GPIO_WritePin(TP8_GPIO_Port, TP8_Pin, GPIO_PIN_RESET);

  /*Configure GPIO pins : LCD_DB7_Pin LCD_RS_Pin LCD_E_Pin */
  GPIO_InitStruct.Pin = LCD_DB7_Pin|LCD_RS_Pin|LCD_E_Pin;
  GPIO_InitStruct.Mode = GPIO_MODE_OUTPUT_PP;
  GPIO_InitStruct.Pull = GPIO_NOPULL;
  GPIO_InitStruct.Speed = GPIO_SPEED_FREQ_LOW;
  HAL_GPIO_Init(GPIOC, &GPIO_InitStruct);

  /*Configure GPIO pins : LCD_DB4_Pin LCD_DB5_Pin LCD_DB6_Pin K_Pin */
  GPIO_InitStruct.Pin = LCD_DB4_Pin|LCD_DB5_Pin|LCD_DB6_Pin|K_Pin;
  GPIO_InitStruct.Mode = GPIO_MODE_OUTPUT_PP;
  GPIO_InitStruct.Pull = GPIO_NOPULL;
  GPIO_InitStruct.Speed = GPIO_SPEED_FREQ_LOW;
  HAL_GPIO_Init(GPIOA, &GPIO_InitStruct);

  /*Configure GPIO pins : PB_SW1_Pin PB_SW2_Pin DSW_3_Pin DSW_4_Pin
                           GPI_PB15_Pin PB_SW3_Pin PB_SW4_Pin */
  GPIO_InitStruct.Pin = PB_SW1_Pin|PB_SW2_Pin|DSW_3_Pin|DSW_4_Pin
                          |GPI_PB15_Pin|PB_SW3_Pin|PB_SW4_Pin;
  GPIO_InitStruct.Mode = GPIO_MODE_INPUT;
  GPIO_InitStruct.Pull = GPIO_NOPULL;
  HAL_GPIO_Init(GPIOB, &GPIO_InitStruct);

  /*Configure GPIO pins : DSW_1_Pin DSW_2_Pin */
  GPIO_InitStruct.Pin = DSW_1_Pin|DSW_2_Pin;
  GPIO_InitStruct.Mode = GPIO_MODE_INPUT;
  GPIO_InitStruct.Pull = GPIO_NOPULL;
  HAL_GPIO_Init(GPIOA, &GPIO_InitStruct);

  /*Configure GPIO pin : TP8_Pin */
  GPIO_InitStruct.Pin = TP8_Pin;
  GPIO_InitStruct.Mode = GPIO_MODE_OUTPUT_PP;
  GPIO_InitStruct.Pull = GPIO_NOPULL;
  GPIO_InitStruct.Speed = GPIO_SPEED_FREQ_LOW;
  HAL_GPIO_Init(TP8_GPIO_Port, &GPIO_InitStruct);

}

void Start_tskUSB(void *argument)
{
  /* init code for USB_Device */
  MX_USB_Device_Init();
  /* USER CODE BEGIN 5 */
  //タスクに依らない初期化処理

  tsk_usb();
  /* Infinite loop */
  for(;;)
  {
    osDelay(1);
  }
  /* USER CODE END 5 */
}

void Start_tskCalc(void *argument)
{
  /* USER CODE BEGIN Start_tskCalc */
  tsk_calc();
  /* Infinite loop */
  for(;;)
  {
    osDelay(1);
  }
  /* USER CODE END Start_tskCalc */
}

void Start_taskUI(void *argument)
{
  /* USER CODE BEGIN Start_taskUI */
  tsk_ui();
  /* Infinite loop */
  for(;;)
  {
    osDelay(1);
  }
  /* USER CODE END Start_taskUI */
}

void Start_taskModbus(void *argument)
{
  /* USER CODE BEGIN Start_taskModbus */
  tsk_modbus_slave();
  /* Infinite loop */
  for(;;)
  {
    osDelay(1);
  }
  /* USER CODE END Start_taskModbus */
}

void HAL_TIM_PeriodElapsedCallback(TIM_HandleTypeDef *htim)
{
  if (htim->Instance == TIM17)
  {
    HAL_IncTick();
  }
  /* USER CODE BEGIN Callback 1 */
  else if (htim->Instance == TIM1)
  {
    KeyScan();
  }
  else if (htim->Instance == TIM2 || htim->Instance == TIM4)
  {
    tsk_calc_timer_overflow_callback(htim);
  }
  /* USER CODE END Callback 1 */
}

void Error_Handler(void)
{
  __disable_irq();
  while (1)
  {
  }
}
